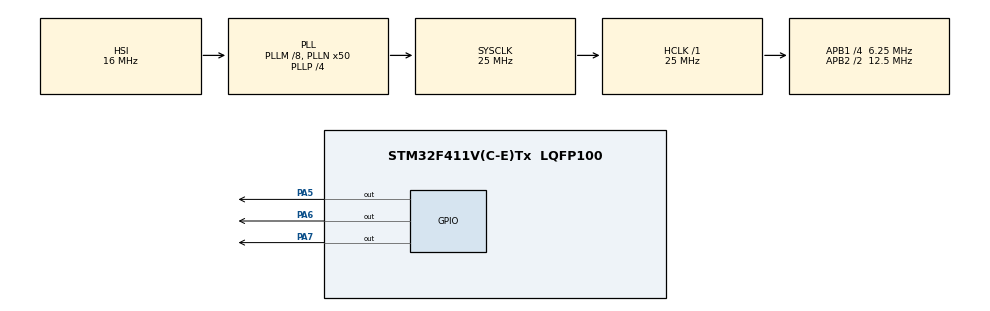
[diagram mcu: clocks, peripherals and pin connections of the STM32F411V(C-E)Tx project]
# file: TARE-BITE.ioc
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Mcu.Family=STM32F4
Mcu.Name=STM32F411V(C-E)Tx
Mcu.Package=LQFP100
NVIC.PriorityGroup=NVIC_PRIORITYGROUP_0
PA5.Signal=GPIO_Output
PA6.Signal=GPIO_Output
PA7.Signal=GPIO_Output
ProjectManager.HeapSize=0x200
ProjectManager.StackSize=0x400
ProjectManager.TargetToolchain=STM32CubeIDE
RCC.48MHZClocksFreq_Value=12500000
RCC.AHBFreq_Value=25000000
RCC.APB1CLKDivider=RCC_HCLK_DIV4
RCC.APB1Freq_Value=6250000
RCC.APB1TimFreq_Value=12500000
RCC.APB2CLKDivider=RCC_HCLK_DIV2
RCC.APB2Freq_Value=12500000
RCC.APB2TimFreq_Value=25000000
RCC.CortexFreq_Value=25000000
RCC.HCLKFreq_Value=25000000
RCC.HSE_VALUE=8000000
RCC.HSI_VALUE=16000000
RCC.PLLI2SM=5
RCC.PLLI2SN=200
RCC.PLLM=8
RCC.PLLN=50
RCC.PLLP=RCC_PLLP_DIV4
RCC.PLLQ=8
RCC.SYSCLKFreq_VALUE=25000000
RCC.SYSCLKSource=RCC_SYSCLKSOURCE_PLLCLK
RCC.VCOOutputFreq_Value=100000000
board=STM32F411E-DISCO

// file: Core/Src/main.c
/* USER CODE BEGIN Header */
/**
  ******************************************************************************
  * @file           : main.c
  * @brief          : Main program body
  ******************************************************************************
  * @attention
  *
  * Copyright (c) 2024 STMicroelectronics.
  * All rights reserved.
  *
  * This software is licensed under terms that can be found in the LICENSE file
  * in the root directory of this software component.
  * If no LICENSE file comes with this software, it is provided AS-IS.
  *
  ******************************************************************************
  */
/* USER CODE END Header */
#include "main.h"
#include "gpio.h"

/* USER CODE BEGIN PD */
#define TARE_TEMPORARY 1
#define TARE_PERMANENT 2
/* USER CODE END PD */

void SystemClock_Config(void);
void activate_BITE(void);
void activate_TARE(uint8_t tare_type);

int main(void)
{

  /* MCU Configuration--------------------------------------------------------*/

  /* Reset of all peripherals, Initializes the Flash interface and the Systick. */
  HAL_Init();

  /* Configure the system clock */
  SystemClock_Config();

  /* Initialize all configured peripherals */
  MX_GPIO_Init();

  /* Infinite loop */
  while (1)
  {

    /* USER CODE BEGIN 3 */
	    activate_BITE();
	    HAL_Delay(600000); // Delay for 10 minutes
	    activate_TARE(TARE_TEMPORARY); // Or TARE_PERMANENT
	    HAL_Delay(1000); // Delay for debouncing after button press
  }
  /* USER CODE END 3 */
}

/*
 *
 *
 * *

*/
void activate_BITE(void) {
  HAL_GPIO_WritePin(GPIOA, GPIO_PIN_5, GPIO_PIN_RESET); // Set B.I.T.E. pin low
  HAL_Delay(1100);                                       // Delay for at least 1 second (with debouncing)
  HAL_GPIO_WritePin(GPIOA, GPIO_PIN_5, GPIO_PIN_SET);    // Set B.I.T.E. pin high again
}

/*
 *
 */

void activate_TARE(uint8_t tare_type) {
  // Set TARE pin to high impedance
  HAL_GPIO_WritePin(GPIOA, GPIO_PIN_6, GPIO_PIN_SET);

  // Implement +24VDC control using a separate GPIO pin (assuming GPIO Port B, pin 7)
  // Replace with your specific GPIO configuration and error handling

  GPIO_InitTypeDef VDC_Pin_InitStruct;
  VDC_Pin_InitStruct.Pin = GPIO_PIN_7;
  VDC_Pin_InitStruct.Mode = GPIO_MODE_OUTPUT_PP;
  VDC_Pin_InitStruct.Pull = GPIO_NOPULL;
  VDC_Pin_InitStruct.Speed = GPIO_SPEED_FREQ_LOW;
  HAL_GPIO_Init(GPIOB, &VDC_Pin_InitStruct);

  if (tare_type == TARE_TEMPORARY) {
    // Provide +24VDC for temporary TARE (adjust timing based on sensor manual)
    HAL_GPIO_WritePin(GPIOB, GPIO_PIN_7, GPIO_PIN_SET);
    HAL_Delay(1000); // Delay for temporary TARE
  } else if (tare_type == TARE_PERMANENT) {
    // Provide +24VDC for permanent TARE (adjust timing based on sensor manual)
    HAL_GPIO_WritePin(GPIOB, GPIO_PIN_7, GPIO_PIN_SET);
    HAL_Delay(3000); // Delay for permanent TARE
  } else {
    // Handle invalid tare_type
  }

  // Turn off +24VDC after TARE activation
  HAL_GPIO_WritePin(GPIOB, GPIO_PIN_7, GPIO_PIN_RESET);
}

/*
 *
 */
void SystemClock_Config(void)
{
  RCC_OscInitTypeDef RCC_OscInitStruct = {0};
  RCC_ClkInitTypeDef RCC_ClkInitStruct = {0};

  /** Configure the main internal regulator output voltage
  */
  __HAL_RCC_PWR_CLK_ENABLE();
  __HAL_PWR_VOLTAGESCALING_CONFIG(PWR_REGULATOR_VOLTAGE_SCALE1);

  /** Initializes the RCC Oscillators according to the specified parameters
  * in the RCC_OscInitTypeDef structure.
  */
  RCC_OscInitStruct.OscillatorType = RCC_OSCILLATORTYPE_HSI;
  RCC_OscInitStruct.HSIState = RCC_HSI_ON;
  RCC_OscInitStruct.HSICalibrationValue = RCC_HSICALIBRATION_DEFAULT;
  RCC_OscInitStruct.PLL.PLLState = RCC_PLL_ON;
  RCC_OscInitStruct.PLL.PLLSource = RCC_PLLSOURCE_HSI;
  RCC_OscInitStruct.PLL.PLLM = 8;
  RCC_OscInitStruct.PLL.PLLN = 50;
  RCC_OscInitStruct.PLL.PLLP = RCC_PLLP_DIV4;
  RCC_OscInitStruct.PLL.PLLQ = 8;
  if (HAL_RCC_OscConfig(&RCC_OscInitStruct) != HAL_OK)
  {
    Error_Handler();
  }

  /** Initializes the CPU, AHB and APB buses clocks
  */
  RCC_ClkInitStruct.ClockType = RCC_CLOCKTYPE_HCLK|RCC_CLOCKTYPE_SYSCLK
                              |RCC_CLOCKTYPE_PCLK1|RCC_CLOCKTYPE_PCLK2;
  RCC_ClkInitStruct.SYSCLKSource = RCC_SYSCLKSOURCE_PLLCLK;
  RCC_ClkInitStruct.AHBCLKDivider = RCC_SYSCLK_DIV1;
  RCC_ClkInitStruct.APB1CLKDivider = RCC_HCLK_DIV4;
  RCC_ClkInitStruct.APB2CLKDivider = RCC_HCLK_DIV2;

  if (HAL_RCC_ClockConfig(&RCC_ClkInitStruct, FLASH_LATENCY_0) != HAL_OK)
  {
    Error_Handler();
  }
}

void Error_Handler(void)
{
  __disable_irq();
  while (1)
  {
  }
}
